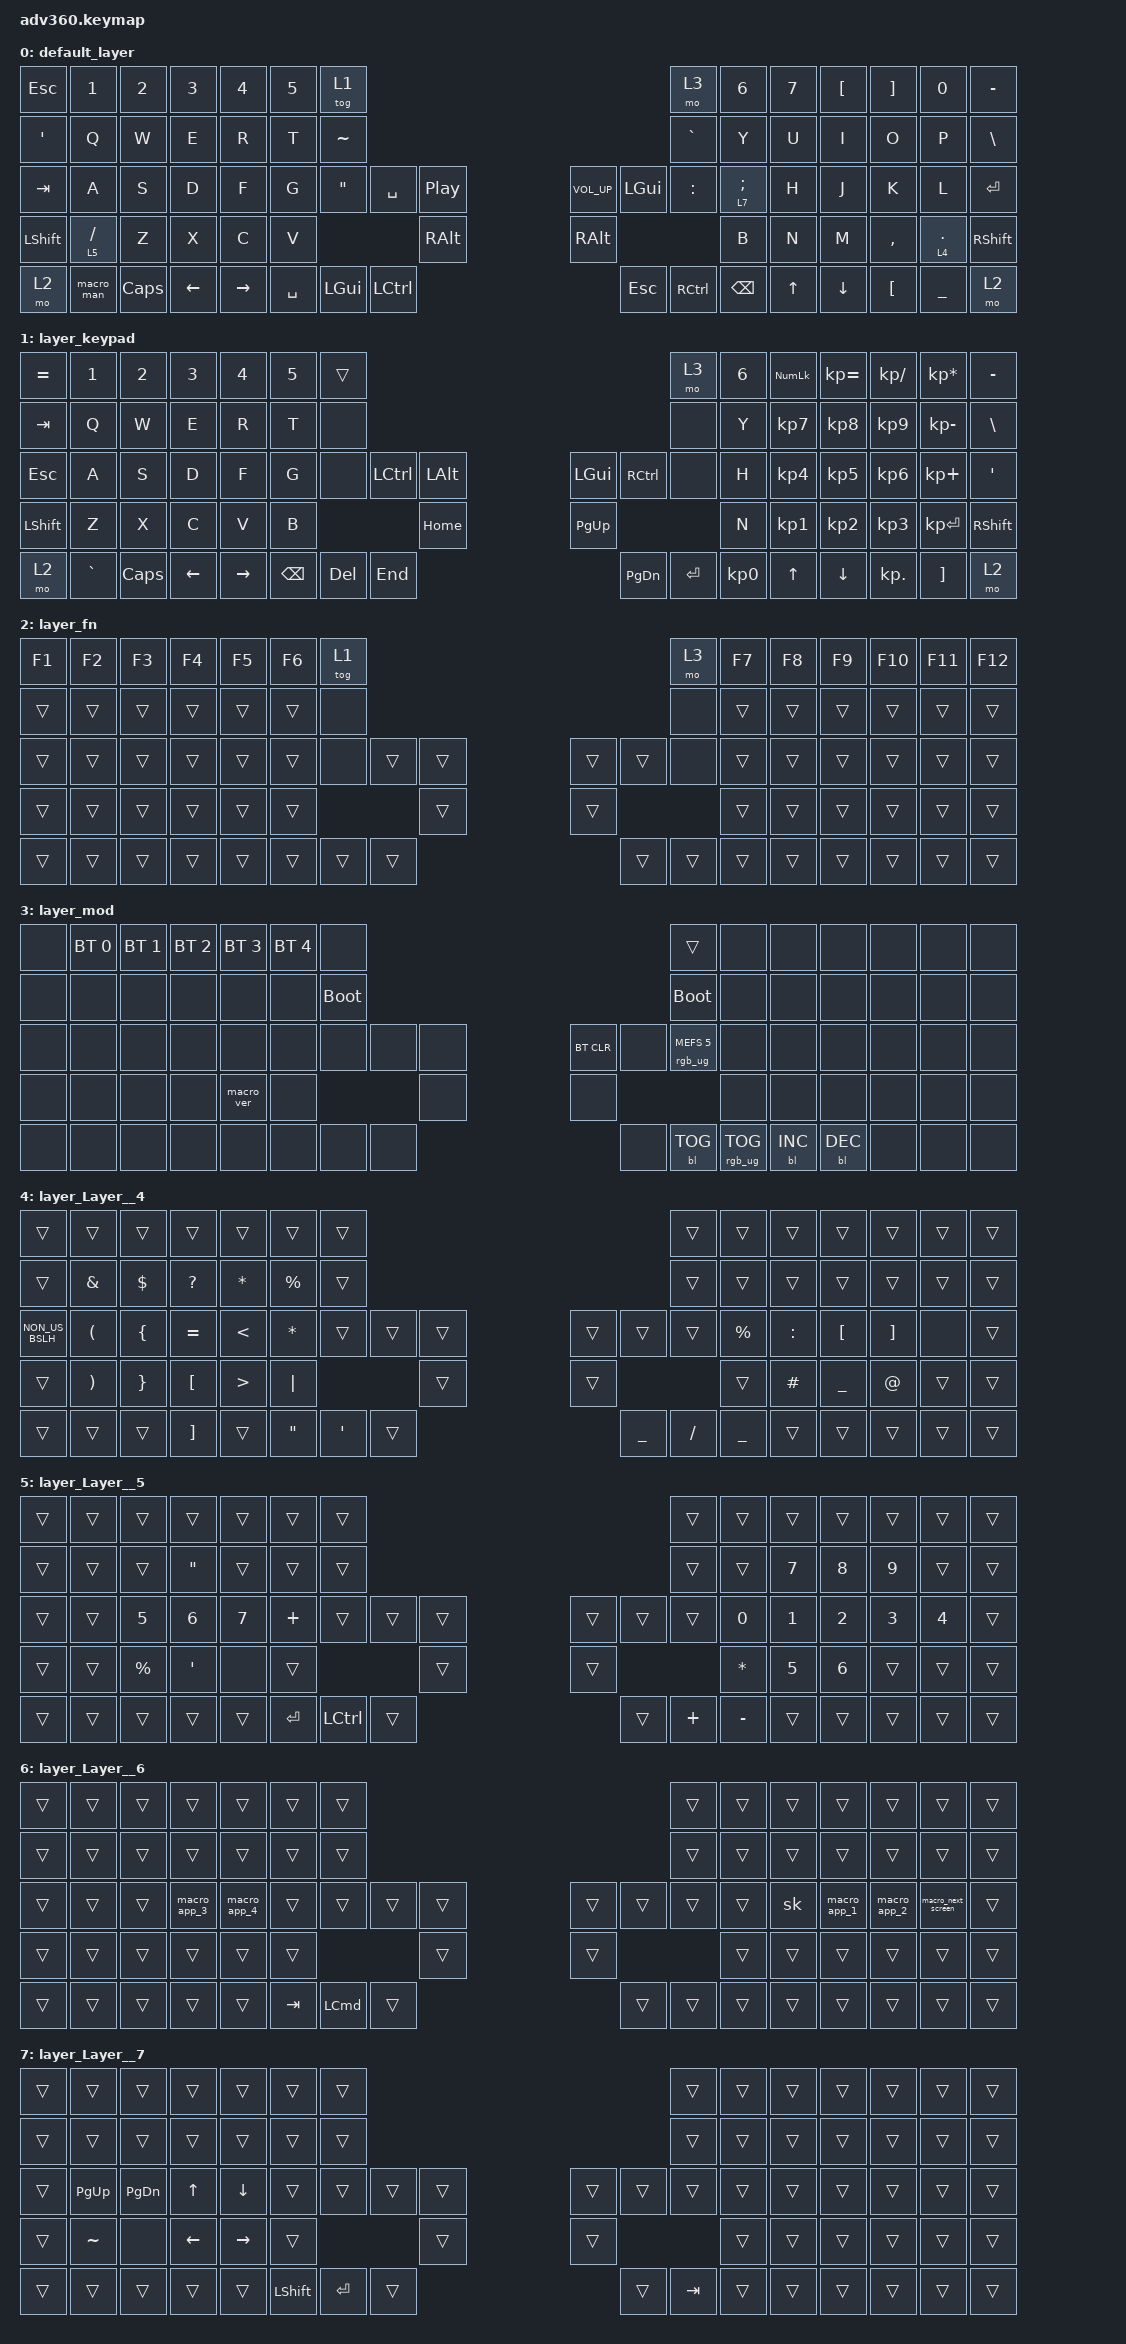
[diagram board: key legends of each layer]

/*
 * Copyright (c) 2020 The ZMK Contributors
 *
 * SPDX-License-Identifier: MIT
 */


/* THIS FILE WAS GENERATED!
 *
 * This file was generated automatically. You may or may not want to
 * edit it directly.
 */

#include <behaviors.dtsi>
#include <dt-bindings/zmk/keys.h>
#include <dt-bindings/zmk/bt.h>
#include <dt-bindings/zmk/rgb.h>
#include <dt-bindings/zmk/backlight.h>

/ {
  behaviors {
    #include "macros.dtsi"
    #include "version.dtsi"

    hm: homerow_mods {
        compatible = "zmk,behavior-hold-tap";
        label = "HOMEROW_MODS";
        #binding-cells = <2>;
        tapping-term-ms = <200>;
        quick_tap_ms = <175>;
        flavor = "tap-preferred";
        bindings = <&kp>, <&kp>;
    };
  };

    keymap {
        compatible = "zmk,keymap";


        default_layer {
            bindings = <
          &kp ESC      &kp N1    &kp N2    &kp N3     &kp N4  &kp N5                       &tog 1                                                                                   &mo 3           &kp N6  &kp N7  &kp LEFT_BRACKET  &kp RIGHT_BRACKET     &kp N0      &kp MINUS
 &kp SINGLE_QUOTE       &kp Q     &kp W     &kp E      &kp R   &kp T                    &kp TILDE                                                                               &kp GRAVE            &kp Y   &kp U             &kp I              &kp O      &kp P  &kp BACKSLASH
          &kp TAB       &kp A     &kp S     &kp D      &kp F   &kp G            &kp DOUBLE_QUOTES     &kp SPACE  &kp C_PLAY_PAUSE                  &kp C_VOL_UP   &kp LGUI      &kp COLON  &lt 7 SEMICOLON   &kp H             &kp J              &kp K      &kp L      &kp ENTER
        &kp LSHFT  &lt 5 FSLH     &kp Z     &kp X      &kp C   &kp V                                                &kp RIGHT_ALT                      &kp RALT                                      &kp B   &kp N             &kp M          &kp COMMA  &lt 4 DOT      &kp RSHFT
            &mo 2  &macro_man  &kp CAPS  &kp LEFT  &kp RIGHT                            &kp SPACE  &kp LEFT_GUI         &kp LCTRL                       &kp ESC  &kp RCTRL  &kp BACKSPACE                   &kp UP          &kp DOWN           &kp LBKT  &kp UNDER          &mo 2
            >;
        };

        layer_keypad {
            bindings = <
 &kp EQUAL     &kp N1    &kp N2    &kp N3     &kp N4  &kp N5              &trans                                                                 &mo 3  &kp N6  &kp KP_NUM  &kp KP_EQUAL  &kp KP_DIVIDE  &kp KP_MULTIPLY  &kp MINUS
   &kp TAB      &kp Q     &kp W     &kp E      &kp R   &kp T               &none                                                                 &none   &kp Y   &kp KP_N7     &kp KP_N8      &kp KP_N9     &kp KP_MINUS   &kp BSLH
   &kp ESC      &kp A     &kp S     &kp D      &kp F   &kp G               &none  &kp LCTRL  &kp LALT                   &kp LGUI  &kp RCTRL      &none   &kp H   &kp KP_N4     &kp KP_N5      &kp KP_N6      &kp KP_PLUS    &kp SQT
 &kp LSHFT      &kp Z     &kp X     &kp C      &kp V   &kp B                                 &kp HOME                  &kp PG_UP                         &kp N   &kp KP_N1     &kp KP_N2      &kp KP_N3     &kp KP_ENTER  &kp RSHFT
     &mo 2  &kp GRAVE  &kp CAPS  &kp LEFT  &kp RIGHT                    &kp BSPC    &kp DEL   &kp END                  &kp PG_DN  &kp ENTER  &kp KP_N0              &kp UP      &kp DOWN     &kp KP_DOT         &kp RBKT      &mo 2
            >;
        };

        layer_fn {
            bindings = <
 &kp F1  &kp F2  &kp F3  &kp F4  &kp F5  &kp F6            &tog 1                                                   &mo 3  &kp F7  &kp F8  &kp F9  &kp F10  &kp F11  &kp F12
 &trans  &trans  &trans  &trans  &trans  &trans             &none                                                   &none  &trans  &trans  &trans   &trans   &trans   &trans
 &trans  &trans  &trans  &trans  &trans  &trans             &none  &trans  &trans                  &trans  &trans   &none  &trans  &trans  &trans   &trans   &trans   &trans
 &trans  &trans  &trans  &trans  &trans  &trans                            &trans                  &trans                  &trans  &trans  &trans   &trans   &trans   &trans
 &trans  &trans  &trans  &trans  &trans                    &trans  &trans  &trans                  &trans  &trans  &trans          &trans  &trans   &trans   &trans   &trans
            >;
        };

        layer_mod {
            bindings = <
  &none  &bt BT_SEL 0  &bt BT_SEL 1  &bt BT_SEL 2  &bt BT_SEL 3  &bt BT_SEL 4                  &none                                                                          &trans   &none       &none       &none   &none   &none   &none
  &none         &none         &none         &none         &none         &none            &bootloader                                                                     &bootloader   &none       &none       &none   &none   &none   &none
  &none         &none         &none         &none         &none         &none                  &none   &none   &none                  &bt BT_CLR       &none  &rgb_ug RGB_MEFS_CMD 5   &none       &none       &none   &none   &none   &none
  &none         &none         &none         &none    &macro_ver         &none                                  &none                       &none                                       &none       &none       &none   &none   &none   &none
  &none         &none         &none         &none         &none                                &none   &none   &none                       &none  &bl BL_TOG         &rgb_ug RGB_TOG          &bl BL_INC  &bl BL_DEC   &none   &none   &none
            >;
        };

        layer_Layer__4 {
            bindings = <
          &trans                 &trans           &trans             &trans            &trans        &trans                       &trans                                                                              &trans       &trans     &trans            &trans             &trans  &trans  &trans
          &trans          &kp AMPERSAND       &kp DOLLAR          &kp QMARK      &kp ASTERISK   &kp PERCENT                       &trans                                                                              &trans       &trans     &trans            &trans             &trans  &trans  &trans
 &kp NON_US_BSLH   &kp LEFT_PARENTHESIS   &kp LEFT_BRACE          &kp EQUAL     &kp LESS_THAN  &kp ASTERISK                       &trans            &trans  &trans                          &trans    &trans          &trans  &kp PERCENT  &kp COLON  &kp LEFT_BRACKET  &kp RIGHT_BRACKET   &none  &trans
          &trans  &kp RIGHT_PARENTHESIS  &kp RIGHT_BRACE   &kp LEFT_BRACKET  &kp GREATER_THAN      &kp PIPE                                                 &trans                          &trans                                 &trans   &kp HASH    &kp UNDERSCORE        &kp AT_SIGN  &trans  &trans
          &trans                 &trans           &trans  &kp RIGHT_BRACKET            &trans                          &kp DOUBLE_QUOTES  &kp SINGLE_QUOTE  &trans                  &kp UNDERSCORE  &kp FSLH  &kp UNDERSCORE                  &trans            &trans             &trans  &trans  &trans
            >;
        };

        layer_Layer__5 {
            bindings = <
 &trans  &trans        &trans             &trans        &trans    &trans               &trans                                                          &trans    &trans  &trans  &trans  &trans  &trans  &trans
 &trans  &trans        &trans  &kp DOUBLE_QUOTES        &trans    &trans               &trans                                                          &trans    &trans  &kp N7  &kp N8  &kp N9  &trans  &trans
 &trans  &trans  &kp NUMBER_5       &kp NUMBER_6  &kp NUMBER_7  &kp PLUS               &trans     &trans  &trans                  &trans    &trans     &trans    &kp N0  &kp N1  &kp N2  &kp N3  &kp N4  &trans
 &trans  &trans   &kp PERCENT   &kp SINGLE_QUOTE         &none    &trans                                  &trans                  &trans                       &kp STAR  &kp N5  &kp N6  &trans  &trans  &trans
 &trans  &trans        &trans             &trans        &trans                      &kp ENTER  &kp LCTRL  &trans                  &trans  &kp PLUS  &kp MINUS            &trans  &trans  &trans  &trans  &trans
            >;
        };

        layer_Layer__6 {
            bindings = <
 &trans  &trans  &trans        &trans        &trans  &trans             &trans                                                            &trans  &trans  &trans        &trans        &trans              &trans  &trans
 &trans  &trans  &trans        &trans        &trans  &trans             &trans                                                            &trans  &trans  &trans        &trans        &trans              &trans  &trans
 &trans  &trans  &trans  &macro_app_3  &macro_app_4  &trans             &trans            &trans  &trans                  &trans  &trans  &trans  &trans     &sk  &macro_app_1  &macro_app_2  &macro_next_screen  &trans
 &trans  &trans  &trans        &trans        &trans  &trans                                       &trans                  &trans                  &trans  &trans        &trans        &trans              &trans  &trans
 &trans  &trans  &trans        &trans        &trans                    &kp TAB  &kp LEFT_COMMAND  &trans                  &trans  &trans  &trans          &trans        &trans        &trans              &trans  &trans
            >;
        };

        layer_Layer__7 {
            bindings = <
 &trans       &trans         &trans    &trans     &trans  &trans                    &trans                                                      &trans  &trans  &trans  &trans  &trans  &trans  &trans
 &trans       &trans         &trans    &trans     &trans  &trans                    &trans                                                      &trans  &trans  &trans  &trans  &trans  &trans  &trans
 &trans  &kp PAGE_UP  &kp PAGE_DOWN    &kp UP   &kp DOWN  &trans                    &trans     &trans  &trans                  &trans   &trans  &trans  &trans  &trans  &trans  &trans  &trans  &trans
 &trans    &kp TILDE          &none  &kp LEFT  &kp RIGHT  &trans                                       &trans                  &trans                   &trans  &trans  &trans  &trans  &trans  &trans
 &trans       &trans         &trans    &trans     &trans                    &kp LEFT_SHIFT  &kp ENTER  &trans                  &trans  &kp TAB  &trans          &trans  &trans  &trans  &trans  &trans
            >;
        };

    };
};
